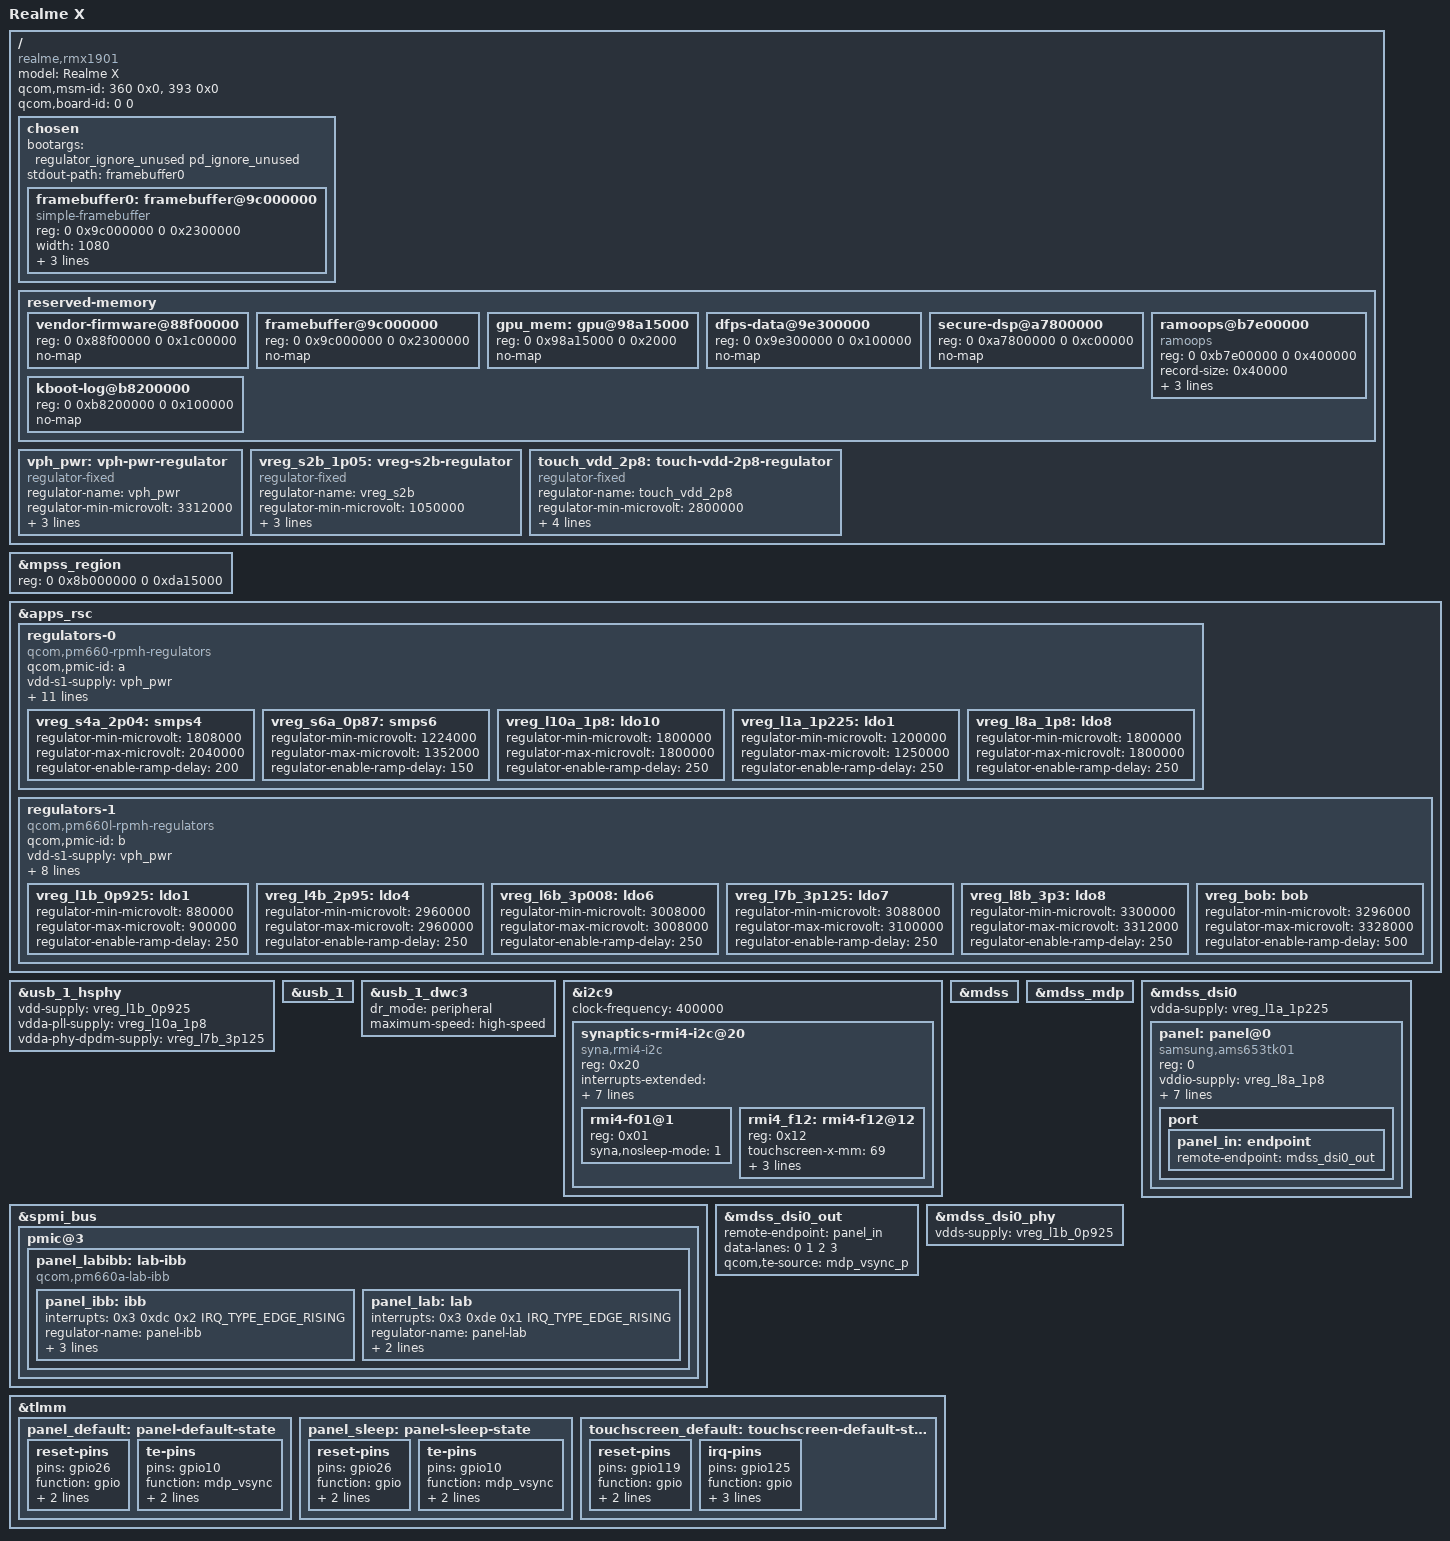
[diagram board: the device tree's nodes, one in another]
// SPDX-License-Identifier: GPL-2.0-only
/*
 * Device tree for the Realme X (RMX1901) recovery kernel.
 *
 * The panel and S3706 touch controller use the mainline DRM/RMI4 paths. The
 * bootloader framebuffer remains available as a fallback during bring-up.
 */

/dts-v1/;

#include "sdm710.dtsi"
#include "pm660.dtsi"
#include "pm660l.dtsi"
#include <dt-bindings/gpio/gpio.h>
#include <dt-bindings/interrupt-controller/irq.h>

/delete-node/ &venus_mem;
/delete-node/ &wlan_msa_mem;
/delete-node/ &cdsp_mem;
/delete-node/ &mba_region;
/delete-node/ &adsp_mem;
/delete-node/ &ipa_fw_mem;
/delete-node/ &ipa_gsi_mem;
/delete-node/ &spss_mem;
/delete-node/ &gpu_mem;

/ {
	model = "Realme X";
	compatible = "realme,rmx1901", "qcom,sdm710", "qcom,sdm670";
	qcom,msm-id = <360 0x0>, <393 0x0>;
	qcom,board-id = <0 0>;

	chosen {
		bootargs = "regulator_ignore_unused pd_ignore_unused";
		stdout-path = "framebuffer0";
		#address-cells = <2>;
		#size-cells = <2>;
		ranges;

		framebuffer0: framebuffer@9c000000 {
			compatible = "simple-framebuffer";
			reg = <0 0x9c000000 0 0x2300000>;
			width = <1080>;
			height = <2340>;
			stride = <4320>;
			format = "a8r8g8b8";
			status = "okay";
		};
	};

	reserved-memory {
		/* The vendor removed region fills the gap before the camera carveout. */
		vendor-firmware@88f00000 {
			reg = <0 0x88f00000 0 0x1c00000>;
			no-map;
		};

		framebuffer@9c000000 {
			reg = <0 0x9c000000 0 0x2300000>;
			no-map;
		};

		gpu_mem: gpu@98a15000 {
			reg = <0 0x98a15000 0 0x2000>;
			no-map;
		};

		dfps-data@9e300000 {
			reg = <0 0x9e300000 0 0x100000>;
			no-map;
		};

		secure-dsp@a7800000 {
			reg = <0 0xa7800000 0 0xc00000>;
			no-map;
		};

		ramoops@b7e00000 {
			compatible = "ramoops";
			reg = <0 0xb7e00000 0 0x400000>;
			record-size = <0x40000>;
			console-size = <0x40000>;
			pmsg-size = <0x200000>;
			ftrace-size = <0x40000>;
		};

		kboot-log@b8200000 {
			reg = <0 0xb8200000 0 0x100000>;
			no-map;
		};
	};

	vph_pwr: vph-pwr-regulator {
		compatible = "regulator-fixed";
		regulator-name = "vph_pwr";
		regulator-min-microvolt = <3312000>;
		regulator-max-microvolt = <3312000>;
		regulator-always-on;
		regulator-boot-on;
	};

	vreg_s2b_1p05: vreg-s2b-regulator {
		compatible = "regulator-fixed";
		regulator-name = "vreg_s2b";
		regulator-min-microvolt = <1050000>;
		regulator-max-microvolt = <1050000>;
		regulator-always-on;
		regulator-boot-on;
	};

	touch_vdd_2p8: touch-vdd-2p8-regulator {
		compatible = "regulator-fixed";
		regulator-name = "touch_vdd_2p8";
		regulator-min-microvolt = <2800000>;
		regulator-max-microvolt = <2800000>;
		regulator-enable-ramp-delay = <100>;

		gpio = <&pm660_gpios 12 GPIO_ACTIVE_HIGH>;
		enable-active-high;
	};
};

/* Coalesce the vendor's overlapping modem/video/DSP carveouts for memblock. */
&mpss_region {
	reg = <0 0x8b000000 0 0xda15000>;
};

&apps_rsc {
	regulators-0 {
		compatible = "qcom,pm660-rpmh-regulators";
		qcom,pmic-id = "a";

		vdd-s1-supply = <&vph_pwr>;
		vdd-s2-supply = <&vph_pwr>;
		vdd-s3-supply = <&vph_pwr>;
		vdd-s4-supply = <&vph_pwr>;
		vdd-s5-supply = <&vph_pwr>;
		vdd-s6-supply = <&vph_pwr>;
		vdd-l1-l6-l7-supply = <&vreg_s6a_0p87>;
		vdd-l2-l3-supply = <&vreg_s2b_1p05>;
		vdd-l5-supply = <&vreg_s2b_1p05>;
		vdd-l8-l9-l10-l11-l12-l13-l14-supply = <&vreg_s4a_2p04>;
		vdd-l15-l16-l17-l18-l19-supply = <&vreg_bob>;

		vreg_s4a_2p04: smps4 {
			regulator-min-microvolt = <1808000>;
			regulator-max-microvolt = <2040000>;
			regulator-enable-ramp-delay = <200>;
		};

		vreg_s6a_0p87: smps6 {
			regulator-min-microvolt = <1224000>;
			regulator-max-microvolt = <1352000>;
			regulator-enable-ramp-delay = <150>;
		};

		vreg_l10a_1p8: ldo10 {
			regulator-min-microvolt = <1800000>;
			regulator-max-microvolt = <1800000>;
			regulator-enable-ramp-delay = <250>;
		};

		vreg_l1a_1p225: ldo1 {
			regulator-min-microvolt = <1200000>;
			regulator-max-microvolt = <1250000>;
			regulator-enable-ramp-delay = <250>;
		};

		vreg_l8a_1p8: ldo8 {
			regulator-min-microvolt = <1800000>;
			regulator-max-microvolt = <1800000>;
			regulator-enable-ramp-delay = <250>;
		};
	};

	regulators-1 {
		compatible = "qcom,pm660l-rpmh-regulators";
		qcom,pmic-id = "b";

		vdd-s1-supply = <&vph_pwr>;
		vdd-s2-supply = <&vph_pwr>;
		vdd-s3-s4-supply = <&vph_pwr>;
		vdd-s5-supply = <&vph_pwr>;
		vdd-l1-l9-l10-supply = <&vreg_s2b_1p05>;
		vdd-l2-supply = <&vreg_bob>;
		vdd-l3-l5-l7-l8-supply = <&vreg_bob>;
		vdd-l4-l6-supply = <&vreg_bob>;
		vdd-bob-supply = <&vph_pwr>;

		vreg_l1b_0p925: ldo1 {
			regulator-min-microvolt = <880000>;
			regulator-max-microvolt = <900000>;
			regulator-enable-ramp-delay = <250>;
		};

		vreg_l4b_2p95: ldo4 {
			regulator-min-microvolt = <2960000>;
			regulator-max-microvolt = <2960000>;
			regulator-enable-ramp-delay = <250>;
		};

		vreg_l6b_3p008: ldo6 {
			regulator-min-microvolt = <3008000>;
			regulator-max-microvolt = <3008000>;
			regulator-enable-ramp-delay = <250>;
		};

		vreg_l7b_3p125: ldo7 {
			regulator-min-microvolt = <3088000>;
			regulator-max-microvolt = <3100000>;
			regulator-enable-ramp-delay = <250>;
		};

		vreg_l8b_3p3: ldo8 {
			regulator-min-microvolt = <3300000>;
			regulator-max-microvolt = <3312000>;
			regulator-enable-ramp-delay = <250>;
		};

		vreg_bob: bob {
			regulator-min-microvolt = <3296000>;
			regulator-max-microvolt = <3328000>;
			regulator-enable-ramp-delay = <500>;
		};
	};
};

&usb_1_hsphy {
	vdd-supply = <&vreg_l1b_0p925>;
	vdda-pll-supply = <&vreg_l10a_1p8>;
	vdda-phy-dpdm-supply = <&vreg_l7b_3p125>;
	status = "okay";
};

&usb_1 {
	status = "okay";
};

&usb_1_dwc3 {
	dr_mode = "peripheral";
	maximum-speed = "high-speed";
};

&i2c9 {
	clock-frequency = <400000>;
	status = "okay";

	synaptics-rmi4-i2c@20 {
		compatible = "syna,rmi4-i2c";
		reg = <0x20>;
		interrupts-extended = <&tlmm 125 IRQ_TYPE_EDGE_FALLING>;

		pinctrl-names = "default";
		pinctrl-0 = <&touchscreen_default>;

		reset-gpios = <&tlmm 119 GPIO_ACTIVE_LOW>;
		vdd-supply = <&touch_vdd_2p8>;
		vio-supply = <&vreg_l8a_1p8>;

		syna,reset-delay-ms = <200>;
		syna,startup-delay-ms = <200>;

		#address-cells = <1>;
		#size-cells = <0>;

		rmi4-f01@1 {
			reg = <0x01>;
			syna,nosleep-mode = <1>;
		};

		rmi4_f12: rmi4-f12@12 {
			reg = <0x12>;
			touchscreen-x-mm = <69>;
			touchscreen-y-mm = <148>;
			syna,sensor-type = <1>;
			syna,rezero-wait-ms = <200>;
		};
	};
};

&mdss {
	status = "okay";
};

&mdss_mdp {
	status = "okay";
};

&mdss_dsi0 {
	vdda-supply = <&vreg_l1a_1p225>;
	status = "okay";

	panel: panel@0 {
		compatible = "samsung,ams653tk01";
		reg = <0>;

		vddio-supply = <&vreg_l8a_1p8>;
		vdda-3p3-supply = <&vreg_l6b_3p008>;
		lab-supply = <&panel_lab>;
		ibb-supply = <&panel_ibb>;

		te-gpios = <&tlmm 10 GPIO_ACTIVE_HIGH>;
		reset-gpios = <&tlmm 26 GPIO_ACTIVE_HIGH>;
		pinctrl-names = "default", "sleep";
		pinctrl-0 = <&panel_default>;
		pinctrl-1 = <&panel_sleep>;

		port {
			panel_in: endpoint {
				remote-endpoint = <&mdss_dsi0_out>;
			};
		};
	};
};

&spmi_bus {
	pmic@3 {
		panel_labibb: lab-ibb {
			compatible = "qcom,pm660a-lab-ibb", "qcom,pmi8998-lab-ibb";
			status = "okay";

			panel_ibb: ibb {
				interrupts = <0x3 0xdc 0x2 IRQ_TYPE_EDGE_RISING>;
				interrupt-names = "sc-err";
				regulator-name = "panel-ibb";
				regulator-min-microvolt = <4000000>;
				regulator-max-microvolt = <6300000>;
				qcom,discharge-resistor-kohms = <300>;
			};

			panel_lab: lab {
				interrupts = <0x3 0xde 0x1 IRQ_TYPE_EDGE_RISING>;
				interrupt-names = "sc-err";
				regulator-name = "panel-lab";
				regulator-min-microvolt = <4600000>;
				regulator-max-microvolt = <6100000>;
			};
		};
	};
};

&mdss_dsi0_out {
	remote-endpoint = <&panel_in>;
	data-lanes = <0 1 2 3>;
	qcom,te-source = "mdp_vsync_p";
};

&mdss_dsi0_phy {
	vdds-supply = <&vreg_l1b_0p925>;
	status = "okay";
};

&tlmm {
	panel_default: panel-default-state {
		reset-pins {
			pins = "gpio26";
			function = "gpio";
			drive-strength = <8>;
			bias-disable;
		};

		te-pins {
			pins = "gpio10";
			function = "mdp_vsync";
			drive-strength = <2>;
			bias-disable;
		};
	};

	panel_sleep: panel-sleep-state {
		reset-pins {
			pins = "gpio26";
			function = "gpio";
			drive-strength = <2>;
			bias-pull-down;
		};

		te-pins {
			pins = "gpio10";
			function = "mdp_vsync";
			drive-strength = <2>;
			bias-disable;
		};
	};

	touchscreen_default: touchscreen-default-state {
		reset-pins {
			pins = "gpio119";
			function = "gpio";
			drive-strength = <8>;
			bias-pull-up;
		};

		irq-pins {
			pins = "gpio125";
			function = "gpio";
			drive-strength = <2>;
			bias-disable;
			input-enable;
		};
	};
};
